# LPC11D14 register map
File version: 4
CPU: 
Registers are 32-bit, read-write, reset 0x0 unless marked. A register's access mark holds for its fields unless they carry their own. Offsets are from the block's base; [hi:lo] are bit positions; {n}, {i} and the like mark numbered series; 'fields as' and 'values as' point back to an identical list.

## CT16B0 — 16-bit counter/timer
Base 0x4000C000
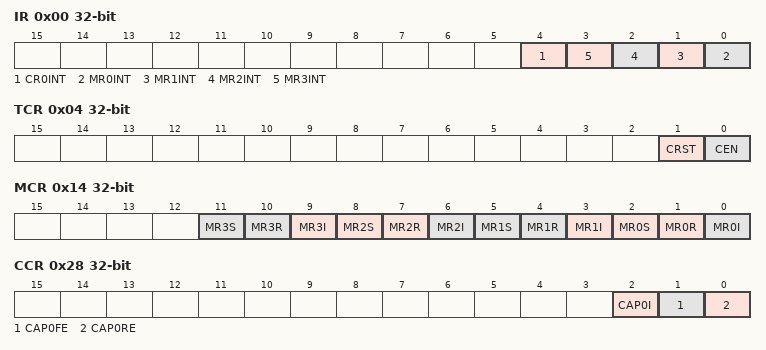
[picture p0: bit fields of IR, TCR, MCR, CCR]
0x00 IR — Interrupt Register (IR). The IR can be written to clear interrupts. The IR can be read to identify which of five possible interrupt sources are pending.
  [4] CR0INT — Interrupt flag for capture channel 0 event.
  [n] MR{n}INT (n=0..3) — Interrupt flag for match channel {n}.
0x04 TCR — Timer Control Register (TCR). The TCR is used to control the Timer Counter functions. The Timer Counter can be disabled or reset through the TCR.
  [1] CRST — Counter Reset. When one, the Timer Counter and the Prescale Counter are synchronously reset on the next positive edge of PCLK. The counters remain reset until TCR[1] is returned to zero.
  [0] CEN — Counter Enable. When one, the Timer Counter and Prescale Counter are enabled for counting. When zero, the counters are disabled.
0x08 TC — Timer Counter (TC). The 16-bit TC is incremented every PR+1 cycles of PCLK. The TC is controlled through the TCR.
  [15:0] TC — Timer counter value.
0x0C PR — Prescale Register (PR). When the Prescale Counter (below) is equal to this value, the next clock increments the TC and clears the PC.
  [15:0] PCVAL — Timer counter value.
0x10 PC — Prescale Counter (PC). The 16-bit PC is a counter which is incremented to the value stored in PR. When the value in PR is reached, the TC is incremented and the PC is cleared. The PC is observable and controllable through the bus interface.
  [15:0] PC — Timer prescale counter value.
0x14 MCR — Match Control Register (MCR). The MCR is used to control if an interrupt is generated and if the TC is reset when a Match occurs.
  [3n+2] MR{n}S (n=0..3) — Stop on MR{n}: the TC and PC will be stopped and TCR[0] will be set to 0 if MR{n} matches the TC.
    1=ENABLED; 0=DISABLED
  [3n+1] MR{n}R (n=0..3) — Reset on MR{n}: the TC will be reset if MR{n} matches it.
    1=ENABLED; 0=DISABLED
  [9] MR3I — Interrupt on MR3: an interrupt is generated when MR3 matches the value in the TC.
    1=ENABLED; 0=DISABLED
  [6] MR2I — Interrupt on MR2: an interrupt is generated when MR2 matches the value in the TC.
    1=ENABLED; 0=DISABLED
  [3] MR1I — Interrupt on MR1: an interrupt is generated when MR1 matches the value in the TC.
    1=ENABLED; 0=DISABLED
  [0] MR0I — Interrupt on MR0: an interrupt is generated when MR0 matches the value in the TC.
    1=ENABLED; 0=D (DISABLED)
{0x18+4i} MR{i} (i=0..3) — Match Register. MR can be enabled through the MCR to reset the TC, stop both the TC and PC, and/or generate an interrupt every time MR matches the TC.
  [15:0] MATCH — Timer counter match value.
0x28 CCR — Capture Control Register (CCR). The CCR controls which edges of the capture inputs are used to load the Capture Registers and whether or not an interrupt is generated when a capture takes place.
  [all] fields
    1=ENABLED; 0=DISABLED
  [2] CAP0I — Interrupt on CT16Bn_CAP0 event: a CR0 load due to a CT16Bn_CAP0 event will generate an interrupt.
  [1] CAP0FE — Capture on CT16Bn_CAP0 falling edge: a sequence of 1 then 0 on CT16Bn_CAP0 will cause CR0 to be loaded with the contents of TC.
  [0] CAP0RE — Capture on CT16Bn_CAP0 rising edge: a sequence of 0 then 1 on CT16Bn_CAP0 will cause CR0 to be loaded with the contents of TC.
0x2C CR0 ro — Capture Register 0 (CR0). CR0 is loaded with the value of TC when there is an event on the CT16B0_CAP0 input.
  [15:0] CAP — Timer counter capture value.
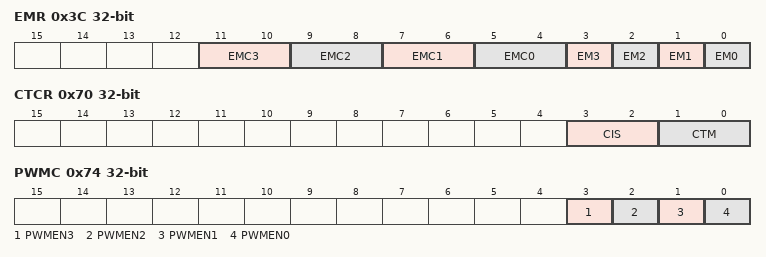
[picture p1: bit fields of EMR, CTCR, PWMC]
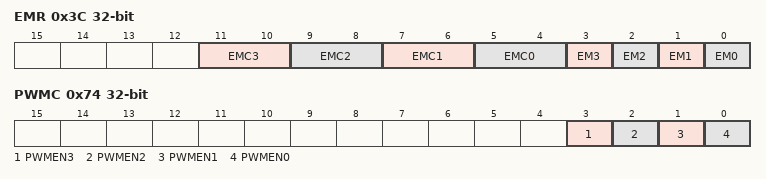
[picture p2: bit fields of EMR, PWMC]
0x3C EMR — External Match Register (EMR). The EMR controls the match function and the external match pins CT16B0_MAT[2:0].
  [11:10] EMC3 — External Match Control 3. Determines the functionality of External Match 3.
    0=DONOTHING; 1=CLEAR (Clear the corresponding External Match bit/output to 0 (CT16Bn_MATm pin is LOW if pinned out).); 2=SET (Set the corresponding External Match bit/output to 1 (CT16Bn_MATm pin is HIGH if pinned out).); 3=TOGGLE (Toggle the corresponding External Match bit/output.)
  [9:8] EMC2 — External Match Control 2. Determines the functionality of External Match 2.
    values as EMC3
  [7:6] EMC1 — External Match Control 1. Determines the functionality of External Match 1.
    0=DONOTHING; 1=CLEAR (Clear the corresponding External Match bit/output to 0 (CT16Bn_MATm pin is LOW if pinned out).); 2=SET (Set the corresponding External Match bit/output to 1 (CT16Bn_MATm pin is HIGH if pinned out).); 3=TOGGLE. (Toggle the corresponding External Match bit/output.)
  [5:4] EMC0 — External Match Control 0. Determines the functionality of External Match 0.
    values as EMC3
  [3] EM3 — External Match 3. This bit reflects the state of output of match channel 3. When a match occurs between the TC and MR3, this bit can either toggle, go LOW, go HIGH, or do nothing. Bits EMR[11:10] control the functionality of this output. There is no output pin available for this channel on either of the 16-bit timers.
  [2] EM2 — External Match 2. This bit reflects the state of output match channel 2, whether or not this output is connected to its pin. When a match occurs between the TC and MR2, this bit can either toggle, go LOW, go HIGH, or do nothing. Bits EMR[9:8] control the functionality of this output. Note that on counter/timer 0 this match channel is not pinned out. This bit is driven to the CT16B1_MAT2 pin if the match function is selected in the IOCON registers (0 = LOW, 1 = HIGH).
  [1] EM1 — External Match 1. This bit reflects the state of output CT16B0_MAT1/CT16B1_MAT1, whether or not this output is connected to its pin. When a match occurs between the TC and MR1, this bit can either toggle, go LOW, go HIGH, or do nothing. Bits EMR[7:6] control the functionality of this output. This bit is driven to the CT16B0_MAT1/CT16B1_MAT1 pins if the match function is selected in the IOCON registers (0 = LOW, 1 = HIGH).
  [0] EM0 — External Match 0. This bit reflects the state of output CT16B0_MAT0/CT16B1_MAT0, whether or not this output is connected to its pin. When a match occurs between the TC and MR0, this bit can either toggle, go LOW, go HIGH, or do nothing. Bits EMR[5:4] control the functionality of this output. This bit is driven to the CT16B0_MAT0/CT16B1_MAT0 pins if the match function is selected in the IOCON registers (0 = LOW, 1 = HIGH).
0x70 CTCR — Count Control Register (CTCR). The CTCR selects between Timer and Counter mode, and in Counter mode selects the signal and edge(s) for counting.
  [3:2] CIS — Count Input Select. In counter mode (when bits 1:0 in this register are not 00), these bits select which CAP pin is sampled for clocking. Note: If Counter mode is selected in the CTCR register, bits 2:0 in the Capture Control Register (CCR) must be programmed as 000.
    0=CT16Bn_CAP0; 1=Reserved
  [1:0] CTM — Counter/Timer Mode. This field selects which rising PCLK edges can increment Timer's Prescale Counter (PC), or clear PC and increment Timer Counter (TC).
    0=TIMERMODE (Timer Mode: every rising PCLK edge); 1=RISINGEDGE (Counter Mode: TC is incremented on rising edges on the CAP input selected by bits 3:2.); 2=FALLLINGEDGE (Counter Mode: TC is incremented on falling edges on the CAP input selected by bits 3:2.); 3=RISINGFALLINGEDGE (Counter Mode: TC is incremented on both edges on the CAP input selected by bits 3:2.)
0x74 PWMC — PWM Control Register (PWMCON). The PWMCON enables PWM mode for the external match pins CT16B0_MAT[2:0].
  [3] PWMEN3 — PWM channel3 enable Note: It is recommended to use match channel 3 to set the PWM cycle because it is not pinned out.
    0=EM3. (Match channel 3 match channel 3 is controlled by EM3.); 1=PWMMODE (PWM mode is enabled for match channel 3match channel 3.)
  [2] PWMEN2 — PWM channel2 enable
    0=EM2 (Match channel 2 or pin CT16B0_MAT2 is controlled by EM2. Match channel 2 is not pinned out on timer 1.); 1=PWMMODE (PWM mode is enabled for match channel 2 or pin CT16B0_MAT2.)
  [1] PWMEN1 — PWM channel1 enable
    0=EM1 (CT16Bn_MAT1 is controlled by EM1.); 1=PWMMODE (PWM mode is enabled for CT16Bn_MAT1.)
  [0] PWMEN0 — PWM channel0 enable
    0=EM0 (CT16Bn_MAT0 is controlled by EM0.); 1=PWMMODE (PWM mode is enabled for CT16Bn_MAT0.)

## CT16B1 — 16-bit counter/timer
Base 0x40010000
Registers as CT16B0; these are added or differ:
0x2C CR0 ro — Capture Register 0 (CR0). CR0 is loaded with the value of TC when there is an event on the CT16B0_CAP0 input.
  [15:0] CAP — Timer counter capture value.
0x3C EMR — External Match Register (EMR). The EMR controls the match function and the external match pins CT16B0_MAT[2:0].
  fields as CT16B0.EMR
0x74 PWMC — PWM Control Register (PWMCON). The PWMCON enables PWM mode for the external match pins CT16B0_MAT[2:0].
  fields as CT16B0.PWMC
